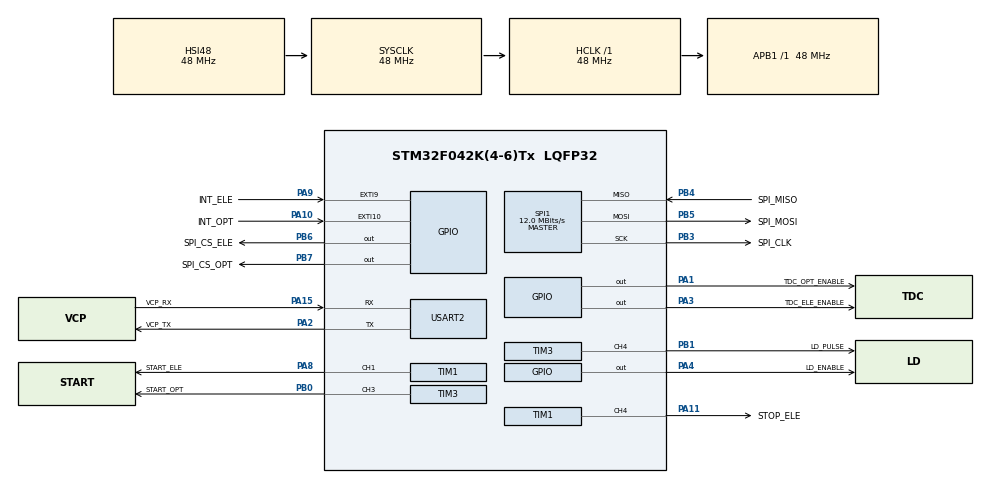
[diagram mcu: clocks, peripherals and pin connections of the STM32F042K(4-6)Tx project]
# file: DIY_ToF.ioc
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Mcu.Family=STM32F0
Mcu.Name=STM32F042K(4-6)Tx
Mcu.Package=LQFP32
PA1.GPIO_Label=TDC_OPT_ENABLE
PA1.Signal=GPIO_Output
PA10.GPIO_Label=INT_OPT
PA10.Signal=GPXTI10
PA11.GPIO_Label=STOP_ELE
PA11.Signal=S_TIM1_CH4
PA13.GPIO_Label=SWDIO
PA13.Mode=Serial_Wire
PA13.Signal=SYS_SWDIO
PA14.GPIO_Label=SWCLK
PA14.Mode=Serial_Wire
PA14.Signal=SYS_SWCLK
PA15.GPIO_Label=VCP_RX
PA15.Mode=Asynchronous
PA15.Signal=USART2_RX
PA2.GPIO_Label=VCP_TX
PA2.Mode=Asynchronous
PA2.Signal=USART2_TX
PA3.GPIO_Label=TDC_ELE_ENABLE
PA3.Signal=GPIO_Output
PA4.GPIO_Label=LD_ENABLE
PA4.Signal=GPIO_Output
PA8.GPIO_Label=START_ELE
PA8.Signal=S_TIM1_CH1
PA9.GPIO_Label=INT_ELE
PA9.Signal=GPXTI9
PB0.GPIO_Label=START_OPT
PB0.Signal=S_TIM3_CH3
PB1.GPIO_Label=LD_PULSE
PB1.Signal=S_TIM3_CH4
PB3.GPIO_Label=SPI_CLK
PB3.Mode=Full_Duplex_Master
PB3.Signal=SPI1_SCK
PB4.GPIO_Label=SPI_MISO
PB4.Mode=Full_Duplex_Master
PB4.Signal=SPI1_MISO
PB5.GPIO_Label=SPI_MOSI
PB5.Mode=Full_Duplex_Master
PB5.Signal=SPI1_MOSI
PB6.GPIO_Label=SPI_CS_ELE
PB6.Signal=GPIO_Output
PB7.GPIO_Label=SPI_CS_OPT
PB7.Signal=GPIO_Output
PF0-OSC_IN.GPIO_Label=MCO
PF0-OSC_IN.Mode=HSE-External-Clock-Source
PF0-OSC_IN.Signal=RCC_OSC_IN
ProjectManager.HeapSize=0x200
ProjectManager.StackSize=0x400
ProjectManager.TargetToolchain=STM32CubeIDE
RCC.AHBFreq_Value=48000000
RCC.APB1Freq_Value=48000000
RCC.APB1TimFreq_Value=48000000
RCC.HCLKFreq_Value=48000000
RCC.SYSCLKFreq_VALUE=48000000
RCC.SYSCLKSource=RCC_SYSCLKSOURCE_HSI48
SH.S_TIM1_CH1.0=TIM1_CH1,Output Compare1 CH1
SH.S_TIM1_CH4.0=TIM1_CH4,Output Compare4 CH4
SH.S_TIM3_CH3.0=TIM3_CH3,Output Compare3 CH3
SH.S_TIM3_CH4.0=TIM3_CH4,Output Compare4 CH4
SPI1.BaudRatePrescaler=SPI_BAUDRATEPRESCALER_4
SPI1.CalculateBaudRate=12.0 MBits/s
SPI1.DataSize=SPI_DATASIZE_8BIT
SPI1.Direction=SPI_DIRECTION_2LINES
SPI1.Mode=SPI_MODE_MASTER
SPI1.NSSPMode=SPI_NSS_PULSE_DISABLE
SPI1.VirtualType=VM_MASTER
TIM1.Channel-Output\ Compare1\ CH1=TIM_CHANNEL_1
TIM1.Channel-Output\ Compare4\ CH4=TIM_CHANNEL_4
TIM1.OCIdleState_1=TIM_OCIDLESTATE_RESET
TIM1.OCIdleState_4=TIM_OCIDLESTATE_RESET
TIM1.OCMode_1=TIM_OCMODE_TOGGLE
TIM1.OCMode_4=TIM_OCMODE_TOGGLE
TIM1.OCPolarity_1=TIM_OCPOLARITY_HIGH
TIM1.OCPolarity_4=TIM_OCPOLARITY_HIGH
TIM1.Pulse-Output\ Compare1\ CH1=32000
TIM1.Pulse-Output\ Compare4\ CH4=32001
TIM3.Channel-Output\ Compare3\ CH3=TIM_CHANNEL_3
TIM3.Channel-Output\ Compare4\ CH4=TIM_CHANNEL_4
TIM3.OCMode_3=TIM_OCMODE_TOGGLE
TIM3.OCMode_4=TIM_OCMODE_TOGGLE
TIM3.Pulse-Output\ Compare3\ CH3=32000
TIM3.Pulse-Output\ Compare4\ CH4=32001
USART2.VirtualMode-Asynchronous=VM_ASYNC
VP_TIM1_VS_ClockSourceINT.Mode=Internal
VP_TIM1_VS_OPM.Mode=OPM_bit
VP_TIM3_VS_ClockSourceINT.Mode=Internal
VP_TIM3_VS_OPM.Mode=OPM_bit
board=NUCLEO-F042K6

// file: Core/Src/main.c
/* USER CODE BEGIN Header */
/**
  ******************************************************************************
  * @file           : main.c
  * @brief          : Main program body
  ******************************************************************************
  * @attention
  *
  * Copyright (c) 2024 STMicroelectronics.
  * All rights reserved.
  *
  * This software is licensed under terms that can be found in the LICENSE file
  * in the root directory of this software component.
  * If no LICENSE file comes with this software, it is provided AS-IS.
  *
  ******************************************************************************
  */
/* USER CODE END Header */
#include "main.h"

/* USER CODE BEGIN Includes */
#include <stdio.h>
#include <string.h>
#include "TDC/TDC.h"
#include "application.h"

/* USER CODE END Includes */

SPI_HandleTypeDef hspi1;

TIM_HandleTypeDef htim1;
TIM_HandleTypeDef htim3;

UART_HandleTypeDef huart2;

void SystemClock_Config(void);
static void MX_GPIO_Init(void);
static void MX_USART2_UART_Init(void);
static void MX_SPI1_Init(void);
static void MX_TIM1_Init(void);
static void MX_TIM3_Init(void);

int main(void)
{

  /* MCU Configuration--------------------------------------------------------*/

  /* Reset of all peripherals, Initializes the Flash interface and the Systick. */
  HAL_Init();

  /* Configure the system clock */
  SystemClock_Config();

  /* Initialize all configured peripherals */
  MX_GPIO_Init();
  MX_USART2_UART_Init();
  MX_SPI1_Init();
  MX_TIM1_Init();
  MX_TIM3_Init();
  /* USER CODE BEGIN 2 */
//  SetupMsmtEle();
  SetupMsmtOpt();

  /* USER CODE END 2 */

  /* Infinite loop */
  /* USER CODE BEGIN WHILE */
  while (1)
  {
//	  DoMsmtEle();
	  DoMsmtOpt();

    /* USER CODE END WHILE */

  }
}

void SystemClock_Config(void)
{
  RCC_OscInitTypeDef RCC_OscInitStruct = {0};
  RCC_ClkInitTypeDef RCC_ClkInitStruct = {0};

  /** Initializes the RCC Oscillators according to the specified parameters
  * in the RCC_OscInitTypeDef structure.
  */
  RCC_OscInitStruct.OscillatorType = RCC_OSCILLATORTYPE_HSI48;
  RCC_OscInitStruct.HSI48State = RCC_HSI48_ON;
  RCC_OscInitStruct.PLL.PLLState = RCC_PLL_NONE;
  if (HAL_RCC_OscConfig(&RCC_OscInitStruct) != HAL_OK)
  {
    Error_Handler();
  }

  /** Initializes the CPU, AHB and APB buses clocks
  */
  RCC_ClkInitStruct.ClockType = RCC_CLOCKTYPE_HCLK|RCC_CLOCKTYPE_SYSCLK
                              |RCC_CLOCKTYPE_PCLK1;
  RCC_ClkInitStruct.SYSCLKSource = RCC_SYSCLKSOURCE_HSI48;
  RCC_ClkInitStruct.AHBCLKDivider = RCC_SYSCLK_DIV1;
  RCC_ClkInitStruct.APB1CLKDivider = RCC_HCLK_DIV1;

  if (HAL_RCC_ClockConfig(&RCC_ClkInitStruct, FLASH_LATENCY_1) != HAL_OK)
  {
    Error_Handler();
  }
}

static void MX_SPI1_Init(void)
{

  /* SPI1 parameter configuration*/
  hspi1.Instance = SPI1;
  hspi1.Init.Mode = SPI_MODE_MASTER;
  hspi1.Init.Direction = SPI_DIRECTION_2LINES;
  hspi1.Init.DataSize = SPI_DATASIZE_8BIT;
  hspi1.Init.CLKPolarity = SPI_POLARITY_LOW;
  hspi1.Init.CLKPhase = SPI_PHASE_1EDGE;
  hspi1.Init.NSS = SPI_NSS_SOFT;
  hspi1.Init.BaudRatePrescaler = SPI_BAUDRATEPRESCALER_4;
  hspi1.Init.FirstBit = SPI_FIRSTBIT_MSB;
  hspi1.Init.TIMode = SPI_TIMODE_DISABLE;
  hspi1.Init.CRCCalculation = SPI_CRCCALCULATION_DISABLE;
  hspi1.Init.CRCPolynomial = 7;
  hspi1.Init.CRCLength = SPI_CRC_LENGTH_DATASIZE;
  hspi1.Init.NSSPMode = SPI_NSS_PULSE_DISABLE;
  if (HAL_SPI_Init(&hspi1) != HAL_OK)
  {
    Error_Handler();
  }

}

static void MX_TIM1_Init(void)
{

  TIM_ClockConfigTypeDef sClockSourceConfig = {0};
  TIM_MasterConfigTypeDef sMasterConfig = {0};
  TIM_OC_InitTypeDef sConfigOC = {0};
  TIM_BreakDeadTimeConfigTypeDef sBreakDeadTimeConfig = {0};

  htim1.Instance = TIM1;
  htim1.Init.Prescaler = 0;
  htim1.Init.CounterMode = TIM_COUNTERMODE_UP;
  htim1.Init.Period = 65535;
  htim1.Init.ClockDivision = TIM_CLOCKDIVISION_DIV1;
  htim1.Init.RepetitionCounter = 0;
  htim1.Init.AutoReloadPreload = TIM_AUTORELOAD_PRELOAD_DISABLE;
  if (HAL_TIM_Base_Init(&htim1) != HAL_OK)
  {
    Error_Handler();
  }
  sClockSourceConfig.ClockSource = TIM_CLOCKSOURCE_INTERNAL;
  if (HAL_TIM_ConfigClockSource(&htim1, &sClockSourceConfig) != HAL_OK)
  {
    Error_Handler();
  }
  if (HAL_TIM_OC_Init(&htim1) != HAL_OK)
  {
    Error_Handler();
  }
  if (HAL_TIM_OnePulse_Init(&htim1, TIM_OPMODE_SINGLE) != HAL_OK)
  {
    Error_Handler();
  }
  sMasterConfig.MasterOutputTrigger = TIM_TRGO_RESET;
  sMasterConfig.MasterSlaveMode = TIM_MASTERSLAVEMODE_DISABLE;
  if (HAL_TIMEx_MasterConfigSynchronization(&htim1, &sMasterConfig) != HAL_OK)
  {
    Error_Handler();
  }
  sConfigOC.OCMode = TIM_OCMODE_TOGGLE;
  sConfigOC.Pulse = 32000;
  sConfigOC.OCPolarity = TIM_OCPOLARITY_HIGH;
  sConfigOC.OCNPolarity = TIM_OCNPOLARITY_HIGH;
  sConfigOC.OCFastMode = TIM_OCFAST_DISABLE;
  sConfigOC.OCIdleState = TIM_OCIDLESTATE_RESET;
  sConfigOC.OCNIdleState = TIM_OCNIDLESTATE_RESET;
  if (HAL_TIM_OC_ConfigChannel(&htim1, &sConfigOC, TIM_CHANNEL_1) != HAL_OK)
  {
    Error_Handler();
  }
  sConfigOC.Pulse = 32001;
  if (HAL_TIM_OC_ConfigChannel(&htim1, &sConfigOC, TIM_CHANNEL_4) != HAL_OK)
  {
    Error_Handler();
  }
  sBreakDeadTimeConfig.OffStateRunMode = TIM_OSSR_DISABLE;
  sBreakDeadTimeConfig.OffStateIDLEMode = TIM_OSSI_DISABLE;
  sBreakDeadTimeConfig.LockLevel = TIM_LOCKLEVEL_OFF;
  sBreakDeadTimeConfig.DeadTime = 0;
  sBreakDeadTimeConfig.BreakState = TIM_BREAK_DISABLE;
  sBreakDeadTimeConfig.BreakPolarity = TIM_BREAKPOLARITY_HIGH;
  sBreakDeadTimeConfig.AutomaticOutput = TIM_AUTOMATICOUTPUT_DISABLE;
  if (HAL_TIMEx_ConfigBreakDeadTime(&htim1, &sBreakDeadTimeConfig) != HAL_OK)
  {
    Error_Handler();
  }
  HAL_TIM_MspPostInit(&htim1);

}

static void MX_TIM3_Init(void)
{

  TIM_ClockConfigTypeDef sClockSourceConfig = {0};
  TIM_MasterConfigTypeDef sMasterConfig = {0};
  TIM_OC_InitTypeDef sConfigOC = {0};

  htim3.Instance = TIM3;
  htim3.Init.Prescaler = 0;
  htim3.Init.CounterMode = TIM_COUNTERMODE_UP;
  htim3.Init.Period = 65535;
  htim3.Init.ClockDivision = TIM_CLOCKDIVISION_DIV1;
  htim3.Init.AutoReloadPreload = TIM_AUTORELOAD_PRELOAD_DISABLE;
  if (HAL_TIM_Base_Init(&htim3) != HAL_OK)
  {
    Error_Handler();
  }
  sClockSourceConfig.ClockSource = TIM_CLOCKSOURCE_INTERNAL;
  if (HAL_TIM_ConfigClockSource(&htim3, &sClockSourceConfig) != HAL_OK)
  {
    Error_Handler();
  }
  if (HAL_TIM_OC_Init(&htim3) != HAL_OK)
  {
    Error_Handler();
  }
  if (HAL_TIM_OnePulse_Init(&htim3, TIM_OPMODE_SINGLE) != HAL_OK)
  {
    Error_Handler();
  }
  sMasterConfig.MasterOutputTrigger = TIM_TRGO_RESET;
  sMasterConfig.MasterSlaveMode = TIM_MASTERSLAVEMODE_DISABLE;
  if (HAL_TIMEx_MasterConfigSynchronization(&htim3, &sMasterConfig) != HAL_OK)
  {
    Error_Handler();
  }
  sConfigOC.OCMode = TIM_OCMODE_TOGGLE;
  sConfigOC.Pulse = 32000;
  sConfigOC.OCPolarity = TIM_OCPOLARITY_HIGH;
  sConfigOC.OCFastMode = TIM_OCFAST_DISABLE;
  if (HAL_TIM_OC_ConfigChannel(&htim3, &sConfigOC, TIM_CHANNEL_3) != HAL_OK)
  {
    Error_Handler();
  }
  sConfigOC.Pulse = 32001;
  if (HAL_TIM_OC_ConfigChannel(&htim3, &sConfigOC, TIM_CHANNEL_4) != HAL_OK)
  {
    Error_Handler();
  }
  HAL_TIM_MspPostInit(&htim3);

}

static void MX_USART2_UART_Init(void)
{

  huart2.Instance = USART2;
  huart2.Init.BaudRate = 38400;
  huart2.Init.WordLength = UART_WORDLENGTH_8B;
  huart2.Init.StopBits = UART_STOPBITS_1;
  huart2.Init.Parity = UART_PARITY_NONE;
  huart2.Init.Mode = UART_MODE_TX_RX;
  huart2.Init.HwFlowCtl = UART_HWCONTROL_NONE;
  huart2.Init.OverSampling = UART_OVERSAMPLING_16;
  huart2.Init.OneBitSampling = UART_ONE_BIT_SAMPLE_DISABLE;
  huart2.AdvancedInit.AdvFeatureInit = UART_ADVFEATURE_NO_INIT;
  if (HAL_UART_Init(&huart2) != HAL_OK)
  {
    Error_Handler();
  }

}

static void MX_GPIO_Init(void)
{
  GPIO_InitTypeDef GPIO_InitStruct = {0};

  /* GPIO Ports Clock Enable */
  __HAL_RCC_GPIOF_CLK_ENABLE();
  __HAL_RCC_GPIOA_CLK_ENABLE();
  __HAL_RCC_GPIOB_CLK_ENABLE();

  /*Configure GPIO pin Output Level */
  HAL_GPIO_WritePin(GPIOA, TDC_OPT_ENABLE_Pin|TDC_ELE_ENABLE_Pin|LD_ENABLE_Pin, GPIO_PIN_RESET);

  /*Configure GPIO pin Output Level */
  HAL_GPIO_WritePin(GPIOB, SPI_CS_ELE_Pin|SPI_CS_OPT_Pin, GPIO_PIN_RESET);

  /*Configure GPIO pins : TDC_OPT_ENABLE_Pin TDC_ELE_ENABLE_Pin LD_ENABLE_Pin */
  GPIO_InitStruct.Pin = TDC_OPT_ENABLE_Pin|TDC_ELE_ENABLE_Pin|LD_ENABLE_Pin;
  GPIO_InitStruct.Mode = GPIO_MODE_OUTPUT_PP;
  GPIO_InitStruct.Pull = GPIO_NOPULL;
  GPIO_InitStruct.Speed = GPIO_SPEED_FREQ_LOW;
  HAL_GPIO_Init(GPIOA, &GPIO_InitStruct);

  /*Configure GPIO pins : INT_ELE_Pin INT_OPT_Pin */
  GPIO_InitStruct.Pin = INT_ELE_Pin|INT_OPT_Pin;
  GPIO_InitStruct.Mode = GPIO_MODE_IT_RISING;
  GPIO_InitStruct.Pull = GPIO_NOPULL;
  HAL_GPIO_Init(GPIOA, &GPIO_InitStruct);

  /*Configure GPIO pins : SPI_CS_ELE_Pin SPI_CS_OPT_Pin */
  GPIO_InitStruct.Pin = SPI_CS_ELE_Pin|SPI_CS_OPT_Pin;
  GPIO_InitStruct.Mode = GPIO_MODE_OUTPUT_PP;
  GPIO_InitStruct.Pull = GPIO_NOPULL;
  GPIO_InitStruct.Speed = GPIO_SPEED_FREQ_LOW;
  HAL_GPIO_Init(GPIOB, &GPIO_InitStruct);

}

/* USER CODE BEGIN 4 */
void WRP_MX_TIM1_Init(void)
{
	MX_TIM1_Init();
}

void WRP_MX_TIM3_Init(void)
{
	MX_TIM3_Init();
}
/* USER CODE END 4 */

void Error_Handler(void)
{
  __disable_irq();
  while (1)
  {
  }
}
